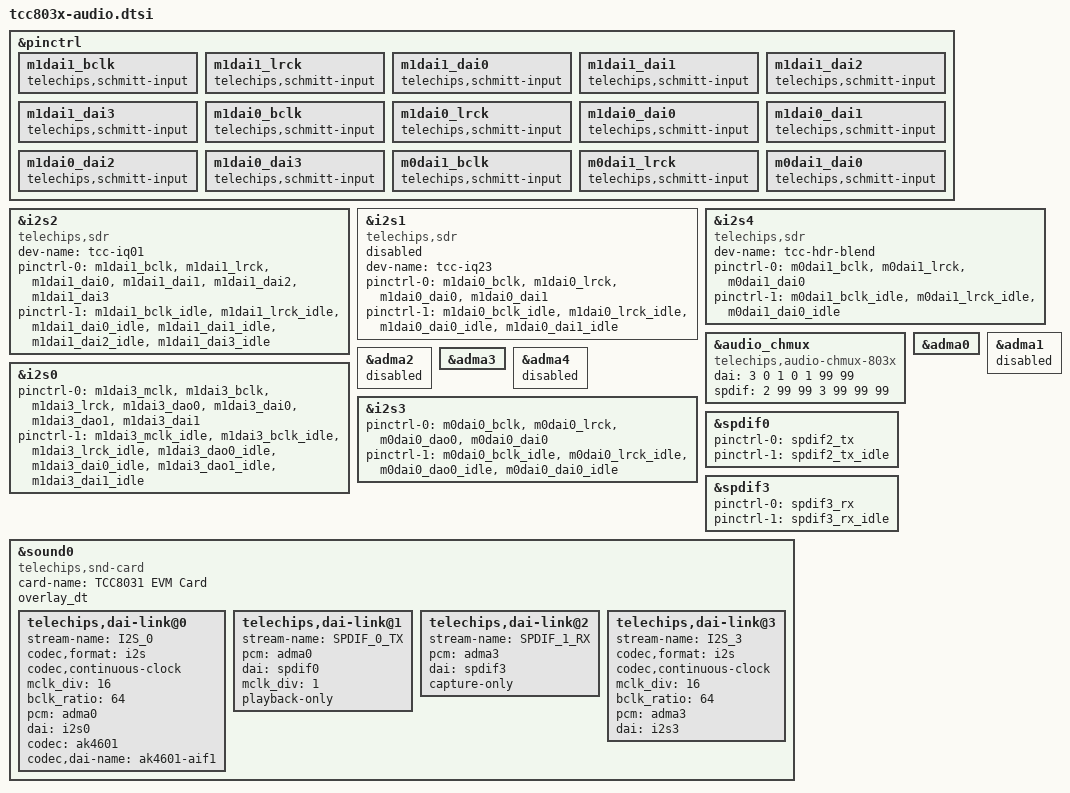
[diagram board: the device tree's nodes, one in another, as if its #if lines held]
//This is for SDR solution.
&pinctrl {
	m1dai1_bclk {
		telechips,schmitt-input;
	};
	m1dai1_lrck {
		telechips,schmitt-input;
	};
	m1dai1_dai0 {
		telechips,schmitt-input;
	};
	m1dai1_dai1 {
		telechips,schmitt-input;
	};
	m1dai1_dai2 {
		telechips,schmitt-input;
	};
	m1dai1_dai3 {
		telechips,schmitt-input;
	};
	m1dai0_bclk {
		telechips,schmitt-input;
	};
	m1dai0_lrck {
		telechips,schmitt-input;
	};
	m1dai0_dai0 {
		telechips,schmitt-input;
	};
	m1dai0_dai1 {
		telechips,schmitt-input;
	};
	m1dai0_dai2 {
		telechips,schmitt-input;
	};
	m1dai0_dai3 {
		telechips,schmitt-input;
	};
	m0dai1_bclk {
		telechips,schmitt-input;
	};
	m0dai1_lrck {
		telechips,schmitt-input;
	};
	m0dai1_dai0 {
		telechips,schmitt-input;
	};
};

/* sdr */
&i2s2 {
	compatible = "telechips,sdr";
	dev-name = "tcc-iq01";
	pinctrl-names = "default", "idle";
	pinctrl-0 = <&m1dai1_bclk &m1dai1_lrck
		     &m1dai1_dai0 &m1dai1_dai1
		     &m1dai1_dai2 &m1dai1_dai3>;
	pinctrl-1 = <&m1dai1_bclk_idle &m1dai1_lrck_idle
		     &m1dai1_dai0_idle &m1dai1_dai1_idle
		     &m1dai1_dai2_idle &m1dai1_dai3_idle>;
	status = "okay";
};

&i2s1 {
	compatible = "telechips,sdr";
	dev-name = "tcc-iq23";
	pinctrl-names = "default", "idle";
	pinctrl-0 = <&m1dai0_bclk &m1dai0_lrck
		     &m1dai0_dai0 &m1dai0_dai1>;
	pinctrl-1 = <&m1dai0_bclk_idle &m1dai0_lrck_idle
		     &m1dai0_dai0_idle &m1dai0_dai1_idle>;
	status = "disabled";
};

&i2s4 {
	compatible = "telechips,sdr";
	dev-name = "tcc-hdr-blend";
	pinctrl-names = "default", "idle";
	pinctrl-0 = <&m0dai1_bclk &m0dai1_lrck &m0dai1_dai0>;
	pinctrl-1 = <&m0dai1_bclk_idle &m0dai1_lrck_idle
		     &m0dai1_dai0_idle>;
	status = "okay";
};

&audio_chmux {
	compatible = "telechips,audio-chmux-803x";
	dai = <3 0 1 0 1 99 99>; // i2s0(x) ... i2s6(x)
	spdif = <2 99 99 3 99 99 99>; // spdif0(x) ... spdif6(x)
	status = "okay";
};

&adma0 {
	status = "okay";
};

&adma1 {
	status = "disabled";
};

&adma2 {
	status = "disabled";
};

&adma3 {
	status = "okay";
};

&adma4 {
	status = "disabled";
};

&i2s0 {
	pinctrl-names = "default", "idle";
	pinctrl-0 = <&m1dai3_mclk &m1dai3_bclk &m1dai3_lrck
		     &m1dai3_dao0 &m1dai3_dai0 &m1dai3_dao1 &m1dai3_dai1>;
	pinctrl-1 = <&m1dai3_mclk_idle &m1dai3_bclk_idle
		     &m1dai3_lrck_idle &m1dai3_dao0_idle
		     &m1dai3_dai0_idle &m1dai3_dao1_idle &m1dai3_dai1_idle>;
	status = "okay";
};

&i2s3 {
	pinctrl-names = "default", "idle";
	pinctrl-0 = <&m0dai0_bclk &m0dai0_lrck
		     &m0dai0_dao0 &m0dai0_dai0>;
	pinctrl-1 = <&m0dai0_bclk_idle &m0dai0_lrck_idle
		     &m0dai0_dao0_idle &m0dai0_dai0_idle>;
	status = "okay";
};

&spdif0 {
	pinctrl-names = "default", "idle";
	pinctrl-0 = <&spdif2_tx>;
	pinctrl-1 = <&spdif2_tx_idle>;
	status = "okay";
};

&spdif3 {
	pinctrl-names = "default", "idle";
	pinctrl-0 = <&spdif3_rx>;
	pinctrl-1 = <&spdif3_rx_idle>;
	status = "okay";
};

/*
&asrc0 {
	sync-mode = <1 1 1 1>; // 0:async, 1:sync
	//path-type = <0 0 0 0>; // 0:m2m, 1:m2p, 2:p2m
	path-type = <1 1 1 2>; // 0:m2m, 1:m2p, 2:p2m
	status = "okay";
};

&sound0 {
	compatible = "telechips,asrc-card";
	card-name = "TCC8031 EVM Card";
	status = "okay";

	asrc = <&asrc0>;

	telechips,dai-link@0 {
		codec,format = "i2s";

		i2s = <&i2s0>;
		codec = <&ak4601>;
		codec,dai-name = "ak4601-aif1";

		asrc-m2p-pairs = <0 1 2>;
		asrc-p2m-pairs = <3>;

		mclk_div = <16>; // 4,6,8,16
		bclk_ratio = <64>; // 32,48,64fs
		samplerate = <48000>;
		format = <0>; // 0:S16LE, 1:S24LE
		channels = <2>; //2, 4, 6, 8
	};
};
*/

&sound0 {
	compatible = "telechips,snd-card";
	card-name = "TCC8031 EVM Card";
	status = "okay";
#ifdef DT_OVERLAY
	overlay_dt;
#endif

	telechips,dai-link@0 {
		stream-name="I2S_0";
		codec,format = "i2s"; // i2s, left_j, right_j
		codec,continuous-clock;
		mclk_div = <16>; // 4,6,8,16
		bclk_ratio = <64>; // 32,48,64fs
		pcm = <&adma0>;
		dai = <&i2s0>;
		codec = <&ak4601>;
		codec,dai-name = "ak4601-aif1";
	};

	telechips,dai-link@1 {
		stream-name="SPDIF_0_TX";
		pcm = <&adma0>;
		dai = <&spdif0>;
		mclk_div = <1>; //for 48Khz sample rate
		playback-only;
	};

	telechips,dai-link@2 {
		stream-name="SPDIF_1_RX";
		pcm = <&adma3>;
		dai = <&spdif3>;
		capture-only;
	};

	telechips,dai-link@3 {
		stream-name="I2S_3";
		codec,format = "i2s"; // i2s, left_j, right_j
		codec,continuous-clock;
		mclk_div = <16>; // 4,6,8,16
		bclk_ratio = <64>; // 32,48,64fs
		pcm = <&adma3>;
		dai = <&i2s3>;
	};
};
